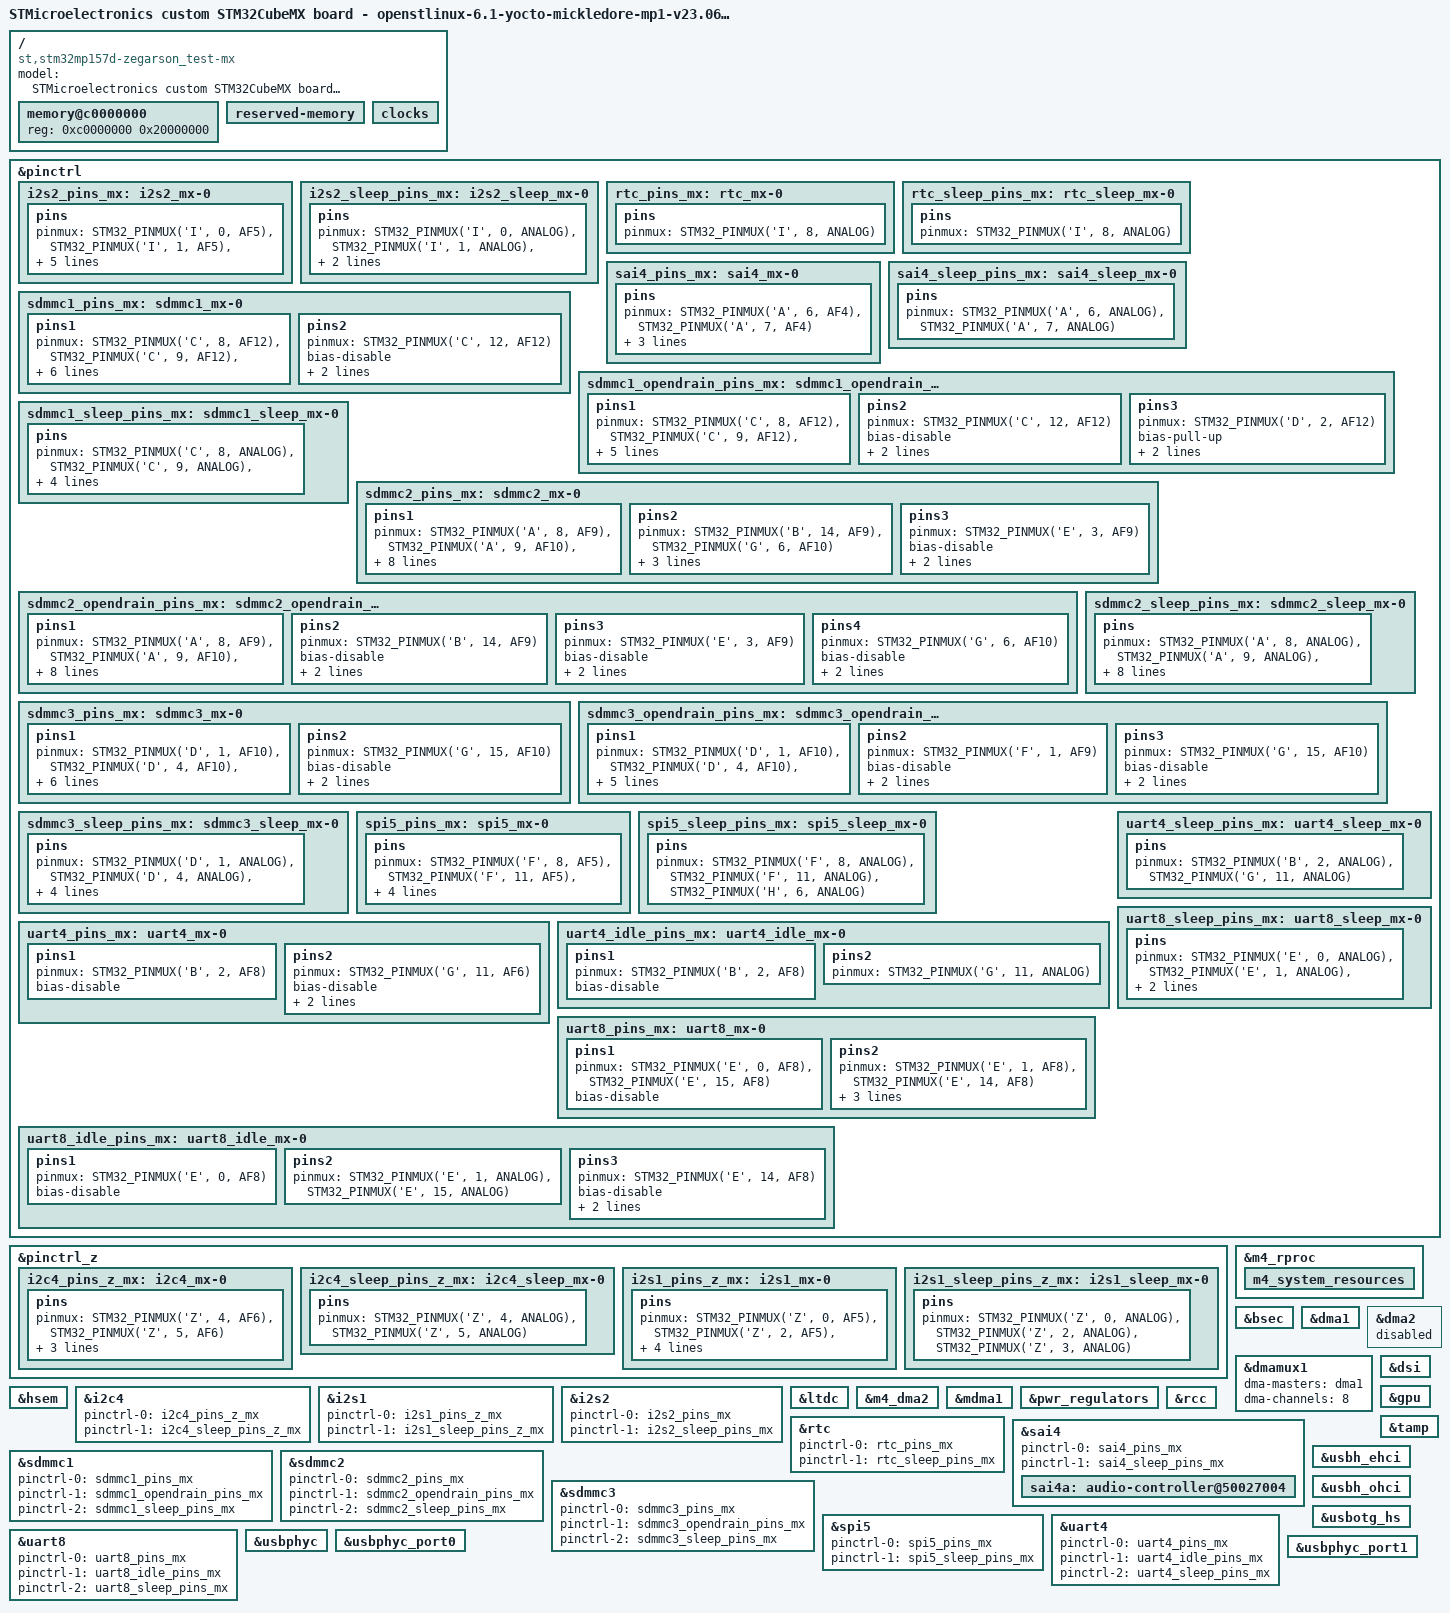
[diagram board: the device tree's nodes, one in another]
// SPDX-License-Identifier: (GPL-2.0-or-later OR BSD-3-Clause)
/*
 * Copyright (C) 2024, STMicroelectronics - All Rights Reserved
 * Author: STM32CubeMX code generation for STMicroelectronics.
 */

/* For more information on Device Tree configuration, please refer to
 * https://wiki.st.com/stm32mpu/wiki/Category:Device_tree_configuration
 */

/dts-v1/;
#include <dt-bindings/pinctrl/stm32-pinfunc.h>

#include "stm32mp157.dtsi"
#include "stm32mp15xd.dtsi"
#include "stm32mp15xxac-pinctrl.dtsi"
#include "stm32mp15-m4-srm.dtsi"

/* USER CODE BEGIN includes */
/* USER CODE END includes */

/ {
	model = "STMicroelectronics custom STM32CubeMX board - openstlinux-6.1-yocto-mickledore-mp1-v23.06.21";
	compatible = "st,stm32mp157d-zegarson_test-mx", "st,stm32mp157";

	memory@c0000000 {
		device_type = "memory";
		reg = <0xc0000000 0x20000000>;

		/* USER CODE BEGIN memory */
		/* USER CODE END memory */
	};

	reserved-memory {
		#address-cells = <1>;
		#size-cells = <1>;
		ranges;

		/* USER CODE BEGIN reserved-memory */
		/* USER CODE END reserved-memory */
	};

	/* USER CODE BEGIN root */
	/* USER CODE END root */

	clocks{

		/* USER CODE BEGIN clocks */
		/* USER CODE END clocks */
	};

}; /*root*/

&pinctrl {

	i2s2_pins_mx: i2s2_mx-0 {
		pins {
			pinmux = <STM32_PINMUX('I', 0, AF5)>, /* I2S2_WS */
					 <STM32_PINMUX('I', 1, AF5)>, /* I2S2_CK */
					 <STM32_PINMUX('I', 2, AF5)>, /* I2S2_SDI */
					 <STM32_PINMUX('I', 3, AF5)>; /* I2S2_SDO */
			bias-disable;
			drive-push-pull;
			slew-rate = <1>;
		};
	};

	i2s2_sleep_pins_mx: i2s2_sleep_mx-0 {
		pins {
			pinmux = <STM32_PINMUX('I', 0, ANALOG)>, /* I2S2_WS */
					 <STM32_PINMUX('I', 1, ANALOG)>, /* I2S2_CK */
					 <STM32_PINMUX('I', 2, ANALOG)>, /* I2S2_SDI */
					 <STM32_PINMUX('I', 3, ANALOG)>; /* I2S2_SDO */
		};
	};

	rtc_pins_mx: rtc_mx-0 {
		pins {
			pinmux = <STM32_PINMUX('I', 8, ANALOG)>; /* RTC_LSCO */
		};
	};

	rtc_sleep_pins_mx: rtc_sleep_mx-0 {
		pins {
			pinmux = <STM32_PINMUX('I', 8, ANALOG)>; /* RTC_LSCO */
		};
	};

	sai4_pins_mx: sai4_mx-0 {
		pins {
			pinmux = <STM32_PINMUX('A', 6, AF4)>, /* SAI4_CK2 */
					 <STM32_PINMUX('A', 7, AF4)>; /* SAI4_D1 */
			bias-disable;
			drive-push-pull;
			slew-rate = <0>;
		};
	};

	sai4_sleep_pins_mx: sai4_sleep_mx-0 {
		pins {
			pinmux = <STM32_PINMUX('A', 6, ANALOG)>, /* SAI4_CK2 */
					 <STM32_PINMUX('A', 7, ANALOG)>; /* SAI4_D1 */
		};
	};

	sdmmc1_pins_mx: sdmmc1_mx-0 {
		pins1 {
			pinmux = <STM32_PINMUX('C', 8, AF12)>, /* SDMMC1_D0 */
					 <STM32_PINMUX('C', 9, AF12)>, /* SDMMC1_D1 */
					 <STM32_PINMUX('C', 10, AF12)>, /* SDMMC1_D2 */
					 <STM32_PINMUX('C', 11, AF12)>, /* SDMMC1_D3 */
					 <STM32_PINMUX('D', 2, AF12)>; /* SDMMC1_CMD */
			bias-pull-up;
			drive-push-pull;
			slew-rate = <1>;
		};
		pins2 {
			pinmux = <STM32_PINMUX('C', 12, AF12)>; /* SDMMC1_CK */
			bias-disable;
			drive-push-pull;
			slew-rate = <3>;
		};
	};

	sdmmc1_opendrain_pins_mx: sdmmc1_opendrain_mx-0 {
		pins1 {
			pinmux = <STM32_PINMUX('C', 8, AF12)>, /* SDMMC1_D0 */
					 <STM32_PINMUX('C', 9, AF12)>, /* SDMMC1_D1 */
					 <STM32_PINMUX('C', 10, AF12)>, /* SDMMC1_D2 */
					 <STM32_PINMUX('C', 11, AF12)>; /* SDMMC1_D3 */
			bias-pull-up;
			drive-push-pull;
			slew-rate = <1>;
		};
		pins2 {
			pinmux = <STM32_PINMUX('C', 12, AF12)>; /* SDMMC1_CK */
			bias-disable;
			drive-push-pull;
			slew-rate = <3>;
		};
		pins3 {
			pinmux = <STM32_PINMUX('D', 2, AF12)>; /* SDMMC1_CMD */
			bias-pull-up;
			drive-open-drain;
			slew-rate = <1>;
		};
	};

	sdmmc1_sleep_pins_mx: sdmmc1_sleep_mx-0 {
		pins {
			pinmux = <STM32_PINMUX('C', 8, ANALOG)>, /* SDMMC1_D0 */
					 <STM32_PINMUX('C', 9, ANALOG)>, /* SDMMC1_D1 */
					 <STM32_PINMUX('C', 10, ANALOG)>, /* SDMMC1_D2 */
					 <STM32_PINMUX('C', 11, ANALOG)>, /* SDMMC1_D3 */
					 <STM32_PINMUX('C', 12, ANALOG)>, /* SDMMC1_CK */
					 <STM32_PINMUX('D', 2, ANALOG)>; /* SDMMC1_CMD */
		};
	};

	sdmmc2_pins_mx: sdmmc2_mx-0 {
		pins1 {
			pinmux = <STM32_PINMUX('A', 8, AF9)>, /* SDMMC2_D4 */
					 <STM32_PINMUX('A', 9, AF10)>, /* SDMMC2_D5 */
					 <STM32_PINMUX('B', 3, AF9)>, /* SDMMC2_D2 */
					 <STM32_PINMUX('B', 4, AF9)>, /* SDMMC2_D3 */
					 <STM32_PINMUX('B', 15, AF9)>, /* SDMMC2_D1 */
					 <STM32_PINMUX('C', 6, AF10)>, /* SDMMC2_D6 */
					 <STM32_PINMUX('C', 7, AF10)>; /* SDMMC2_D7 */
			bias-pull-up;
			drive-push-pull;
			slew-rate = <1>;
		};
		pins2 {
			pinmux = <STM32_PINMUX('B', 14, AF9)>, /* SDMMC2_D0 */
					 <STM32_PINMUX('G', 6, AF10)>; /* SDMMC2_CMD */
			bias-disable;
			drive-push-pull;
			slew-rate = <1>;
		};
		pins3 {
			pinmux = <STM32_PINMUX('E', 3, AF9)>; /* SDMMC2_CK */
			bias-disable;
			drive-push-pull;
			slew-rate = <3>;
		};
	};

	sdmmc2_opendrain_pins_mx: sdmmc2_opendrain_mx-0 {
		pins1 {
			pinmux = <STM32_PINMUX('A', 8, AF9)>, /* SDMMC2_D4 */
					 <STM32_PINMUX('A', 9, AF10)>, /* SDMMC2_D5 */
					 <STM32_PINMUX('B', 3, AF9)>, /* SDMMC2_D2 */
					 <STM32_PINMUX('B', 4, AF9)>, /* SDMMC2_D3 */
					 <STM32_PINMUX('B', 15, AF9)>, /* SDMMC2_D1 */
					 <STM32_PINMUX('C', 6, AF10)>, /* SDMMC2_D6 */
					 <STM32_PINMUX('C', 7, AF10)>; /* SDMMC2_D7 */
			bias-pull-up;
			drive-push-pull;
			slew-rate = <1>;
		};
		pins2 {
			pinmux = <STM32_PINMUX('B', 14, AF9)>; /* SDMMC2_D0 */
			bias-disable;
			drive-push-pull;
			slew-rate = <1>;
		};
		pins3 {
			pinmux = <STM32_PINMUX('E', 3, AF9)>; /* SDMMC2_CK */
			bias-disable;
			drive-push-pull;
			slew-rate = <3>;
		};
		pins4 {
			pinmux = <STM32_PINMUX('G', 6, AF10)>; /* SDMMC2_CMD */
			bias-disable;
			drive-open-drain;
			slew-rate = <1>;
		};
	};

	sdmmc2_sleep_pins_mx: sdmmc2_sleep_mx-0 {
		pins {
			pinmux = <STM32_PINMUX('A', 8, ANALOG)>, /* SDMMC2_D4 */
					 <STM32_PINMUX('A', 9, ANALOG)>, /* SDMMC2_D5 */
					 <STM32_PINMUX('B', 3, ANALOG)>, /* SDMMC2_D2 */
					 <STM32_PINMUX('B', 4, ANALOG)>, /* SDMMC2_D3 */
					 <STM32_PINMUX('B', 14, ANALOG)>, /* SDMMC2_D0 */
					 <STM32_PINMUX('B', 15, ANALOG)>, /* SDMMC2_D1 */
					 <STM32_PINMUX('C', 6, ANALOG)>, /* SDMMC2_D6 */
					 <STM32_PINMUX('C', 7, ANALOG)>, /* SDMMC2_D7 */
					 <STM32_PINMUX('E', 3, ANALOG)>, /* SDMMC2_CK */
					 <STM32_PINMUX('G', 6, ANALOG)>; /* SDMMC2_CMD */
		};
	};

	sdmmc3_pins_mx: sdmmc3_mx-0 {
		pins1 {
			pinmux = <STM32_PINMUX('D', 1, AF10)>, /* SDMMC3_D0 */
					 <STM32_PINMUX('D', 4, AF10)>, /* SDMMC3_D1 */
					 <STM32_PINMUX('D', 5, AF10)>, /* SDMMC3_D2 */
					 <STM32_PINMUX('D', 7, AF10)>, /* SDMMC3_D3 */
					 <STM32_PINMUX('F', 1, AF9)>; /* SDMMC3_CMD */
			bias-disable;
			drive-push-pull;
			slew-rate = <1>;
		};
		pins2 {
			pinmux = <STM32_PINMUX('G', 15, AF10)>; /* SDMMC3_CK */
			bias-disable;
			drive-push-pull;
			slew-rate = <3>;
		};
	};

	sdmmc3_opendrain_pins_mx: sdmmc3_opendrain_mx-0 {
		pins1 {
			pinmux = <STM32_PINMUX('D', 1, AF10)>, /* SDMMC3_D0 */
					 <STM32_PINMUX('D', 4, AF10)>, /* SDMMC3_D1 */
					 <STM32_PINMUX('D', 5, AF10)>, /* SDMMC3_D2 */
					 <STM32_PINMUX('D', 7, AF10)>; /* SDMMC3_D3 */
			bias-disable;
			drive-push-pull;
			slew-rate = <1>;
		};
		pins2 {
			pinmux = <STM32_PINMUX('F', 1, AF9)>; /* SDMMC3_CMD */
			bias-disable;
			drive-open-drain;
			slew-rate = <1>;
		};
		pins3 {
			pinmux = <STM32_PINMUX('G', 15, AF10)>; /* SDMMC3_CK */
			bias-disable;
			drive-push-pull;
			slew-rate = <3>;
		};
	};

	sdmmc3_sleep_pins_mx: sdmmc3_sleep_mx-0 {
		pins {
			pinmux = <STM32_PINMUX('D', 1, ANALOG)>, /* SDMMC3_D0 */
					 <STM32_PINMUX('D', 4, ANALOG)>, /* SDMMC3_D1 */
					 <STM32_PINMUX('D', 5, ANALOG)>, /* SDMMC3_D2 */
					 <STM32_PINMUX('D', 7, ANALOG)>, /* SDMMC3_D3 */
					 <STM32_PINMUX('F', 1, ANALOG)>, /* SDMMC3_CMD */
					 <STM32_PINMUX('G', 15, ANALOG)>; /* SDMMC3_CK */
		};
	};

	spi5_pins_mx: spi5_mx-0 {
		pins {
			pinmux = <STM32_PINMUX('F', 8, AF5)>, /* SPI5_MISO */
					 <STM32_PINMUX('F', 11, AF5)>, /* SPI5_MOSI */
					 <STM32_PINMUX('H', 6, AF5)>; /* SPI5_SCK */
			bias-disable;
			drive-push-pull;
			slew-rate = <1>;
		};
	};

	spi5_sleep_pins_mx: spi5_sleep_mx-0 {
		pins {
			pinmux = <STM32_PINMUX('F', 8, ANALOG)>, /* SPI5_MISO */
					 <STM32_PINMUX('F', 11, ANALOG)>, /* SPI5_MOSI */
					 <STM32_PINMUX('H', 6, ANALOG)>; /* SPI5_SCK */
		};
	};

	uart4_pins_mx: uart4_mx-0 {
		pins1 {
			pinmux = <STM32_PINMUX('B', 2, AF8)>; /* UART4_RX */
			bias-disable;
		};
		pins2 {
			pinmux = <STM32_PINMUX('G', 11, AF6)>; /* UART4_TX */
			bias-disable;
			drive-push-pull;
			slew-rate = <0>;
		};
	};

	uart4_idle_pins_mx: uart4_idle_mx-0 {
		pins1 {
			pinmux = <STM32_PINMUX('B', 2, AF8)>; /* UART4_RX */
			bias-disable;
		};
		pins2 {
			pinmux = <STM32_PINMUX('G', 11, ANALOG)>; /* UART4_TX */
		};
	};

	uart4_sleep_pins_mx: uart4_sleep_mx-0 {
		pins {
			pinmux = <STM32_PINMUX('B', 2, ANALOG)>, /* UART4_RX */
					 <STM32_PINMUX('G', 11, ANALOG)>; /* UART4_TX */
		};
	};

	uart8_pins_mx: uart8_mx-0 {
		pins1 {
			pinmux = <STM32_PINMUX('E', 0, AF8)>, /* UART8_RX */
					 <STM32_PINMUX('E', 15, AF8)>; /* UART8_CTS */
			bias-disable;
		};
		pins2 {
			pinmux = <STM32_PINMUX('E', 1, AF8)>, /* UART8_TX */
					 <STM32_PINMUX('E', 14, AF8)>; /* UART8_RTS */
			bias-disable;
			drive-push-pull;
			slew-rate = <0>;
		};
	};

	uart8_idle_pins_mx: uart8_idle_mx-0 {
		pins1 {
			pinmux = <STM32_PINMUX('E', 0, AF8)>; /* UART8_RX */
			bias-disable;
		};
		pins2 {
			pinmux = <STM32_PINMUX('E', 1, ANALOG)>, /* UART8_TX */
					 <STM32_PINMUX('E', 15, ANALOG)>; /* UART8_CTS */
		};
		pins3 {
			pinmux = <STM32_PINMUX('E', 14, AF8)>; /* UART8_RTS */
			bias-disable;
			drive-push-pull;
			slew-rate = <0>;
		};
	};

	uart8_sleep_pins_mx: uart8_sleep_mx-0 {
		pins {
			pinmux = <STM32_PINMUX('E', 0, ANALOG)>, /* UART8_RX */
					 <STM32_PINMUX('E', 1, ANALOG)>, /* UART8_TX */
					 <STM32_PINMUX('E', 14, ANALOG)>, /* UART8_RTS */
					 <STM32_PINMUX('E', 15, ANALOG)>; /* UART8_CTS */
		};
	};

	/* USER CODE BEGIN pinctrl */
	/* USER CODE END pinctrl */
};

&pinctrl_z {

	i2c4_pins_z_mx: i2c4_mx-0 {
		pins {
			pinmux = <STM32_PINMUX('Z', 4, AF6)>, /* I2C4_SCL */
					 <STM32_PINMUX('Z', 5, AF6)>; /* I2C4_SDA */
			bias-disable;
			drive-open-drain;
			slew-rate = <0>;
		};
	};

	i2c4_sleep_pins_z_mx: i2c4_sleep_mx-0 {
		pins {
			pinmux = <STM32_PINMUX('Z', 4, ANALOG)>, /* I2C4_SCL */
					 <STM32_PINMUX('Z', 5, ANALOG)>; /* I2C4_SDA */
		};
	};

	i2s1_pins_z_mx: i2s1_mx-0 {
		pins {
			pinmux = <STM32_PINMUX('Z', 0, AF5)>, /* I2S1_CK */
					 <STM32_PINMUX('Z', 2, AF5)>, /* I2S1_SDO */
					 <STM32_PINMUX('Z', 3, AF5)>; /* I2S1_WS */
			bias-disable;
			drive-push-pull;
			slew-rate = <1>;
		};
	};

	i2s1_sleep_pins_z_mx: i2s1_sleep_mx-0 {
		pins {
			pinmux = <STM32_PINMUX('Z', 0, ANALOG)>, /* I2S1_CK */
					 <STM32_PINMUX('Z', 2, ANALOG)>, /* I2S1_SDO */
					 <STM32_PINMUX('Z', 3, ANALOG)>; /* I2S1_WS */
		};
	};

	/* USER CODE BEGIN pinctrl_z */
	/* USER CODE END pinctrl_z */
};

&m4_rproc{
	status = "okay";

	/* USER CODE BEGIN m4_rproc */
	/* USER CODE END m4_rproc */

	m4_system_resources{
		status = "okay";

		/* USER CODE BEGIN m4_system_resources */
		/* USER CODE END m4_system_resources */
	};
};

&bsec{
	status = "okay";

	/* USER CODE BEGIN bsec */
	/* USER CODE END bsec */
};

&dma1{
	status = "okay";

	/* USER CODE BEGIN dma1 */
	/* USER CODE END dma1 */
};

&dma2{
	status = "disabled";

	/* USER CODE BEGIN dma2 */
	/* USER CODE END dma2 */
};

&dmamux1{
	status = "okay";

	dma-masters = <&dma1>;
	dma-channels = <8>;

	/* USER CODE BEGIN dmamux1 */
	/* USER CODE END dmamux1 */
};

&dsi{
	status = "okay";

	/* USER CODE BEGIN dsi */
	/* USER CODE END dsi */
};

&gpu{
	status = "okay";

	/* USER CODE BEGIN gpu */
	/* USER CODE END gpu */
};

&hsem{
	status = "okay";

	/* USER CODE BEGIN hsem */
	/* USER CODE END hsem */
};

&i2c4{
	pinctrl-names = "default", "sleep";
	pinctrl-0 = <&i2c4_pins_z_mx>;
	pinctrl-1 = <&i2c4_sleep_pins_z_mx>;
	status = "okay";

	/* USER CODE BEGIN i2c4 */
	/* USER CODE END i2c4 */
};

&i2s1{
	pinctrl-names = "default", "sleep";
	pinctrl-0 = <&i2s1_pins_z_mx>;
	pinctrl-1 = <&i2s1_sleep_pins_z_mx>;
	status = "okay";

	/* USER CODE BEGIN i2s1 */
	/* USER CODE END i2s1 */
};

&i2s2{
	pinctrl-names = "default", "sleep";
	pinctrl-0 = <&i2s2_pins_mx>;
	pinctrl-1 = <&i2s2_sleep_pins_mx>;
	status = "okay";

	/* USER CODE BEGIN i2s2 */
	/* USER CODE END i2s2 */
};

&ltdc{
	status = "okay";

	/* USER CODE BEGIN ltdc */
	/* USER CODE END ltdc */
};

&m4_dma2{
	status = "okay";

	/* USER CODE BEGIN m4_dma2 */
	/* USER CODE END m4_dma2 */
};

&mdma1{
	status = "okay";

	/* USER CODE BEGIN mdma1 */
	/* USER CODE END mdma1 */
};

&pwr_regulators{
	status = "okay";

	/* USER CODE BEGIN pwr_regulators */
	/* USER CODE END pwr_regulators */
};

&rcc{
	status = "okay";

	/* USER CODE BEGIN rcc */
	/* USER CODE END rcc */
};

&rtc{
	pinctrl-names = "default", "sleep";
	pinctrl-0 = <&rtc_pins_mx>;
	pinctrl-1 = <&rtc_sleep_pins_mx>;
	status = "okay";

	/* USER CODE BEGIN rtc */
	/* USER CODE END rtc */
};

&sai4{
	pinctrl-names = "default", "sleep";
	pinctrl-0 = <&sai4_pins_mx>;
	pinctrl-1 = <&sai4_sleep_pins_mx>;
	status = "okay";

	/* USER CODE BEGIN sai4 */
	/* USER CODE END sai4 */

	sai4a:audio-controller@50027004{
		status = "okay";

		/* USER CODE BEGIN sai4a */
		/* USER CODE END sai4a */
	};
};

&sdmmc1{
	pinctrl-names = "default", "opendrain", "sleep";
	pinctrl-0 = <&sdmmc1_pins_mx>;
	pinctrl-1 = <&sdmmc1_opendrain_pins_mx>;
	pinctrl-2 = <&sdmmc1_sleep_pins_mx>;
	status = "okay";

	/* USER CODE BEGIN sdmmc1 */
	/* USER CODE END sdmmc1 */
};

&sdmmc2{
	pinctrl-names = "default", "opendrain", "sleep";
	pinctrl-0 = <&sdmmc2_pins_mx>;
	pinctrl-1 = <&sdmmc2_opendrain_pins_mx>;
	pinctrl-2 = <&sdmmc2_sleep_pins_mx>;
	status = "okay";

	/* USER CODE BEGIN sdmmc2 */
	/* USER CODE END sdmmc2 */
};

&sdmmc3{
	pinctrl-names = "default", "opendrain", "sleep";
	pinctrl-0 = <&sdmmc3_pins_mx>;
	pinctrl-1 = <&sdmmc3_opendrain_pins_mx>;
	pinctrl-2 = <&sdmmc3_sleep_pins_mx>;
	status = "okay";

	/* USER CODE BEGIN sdmmc3 */
	/* USER CODE END sdmmc3 */
};

&spi5{
	pinctrl-names = "default", "sleep";
	pinctrl-0 = <&spi5_pins_mx>;
	pinctrl-1 = <&spi5_sleep_pins_mx>;
	status = "okay";

	/* USER CODE BEGIN spi5 */
	/* USER CODE END spi5 */
};

&tamp{
	status = "okay";

	/* USER CODE BEGIN tamp */
	/* USER CODE END tamp */
};

&uart4{
	pinctrl-names = "default", "idle", "sleep";
	pinctrl-0 = <&uart4_pins_mx>;
	pinctrl-1 = <&uart4_idle_pins_mx>;
	pinctrl-2 = <&uart4_sleep_pins_mx>;
	status = "okay";

	/* USER CODE BEGIN uart4 */
	/* USER CODE END uart4 */
};

&uart8{
	pinctrl-names = "default", "idle", "sleep";
	pinctrl-0 = <&uart8_pins_mx>;
	pinctrl-1 = <&uart8_idle_pins_mx>;
	pinctrl-2 = <&uart8_sleep_pins_mx>;
	status = "okay";

	/* USER CODE BEGIN uart8 */
	/* USER CODE END uart8 */
};

&usbh_ehci{
	status = "okay";

	/* USER CODE BEGIN usbh_ehci */
	/* USER CODE END usbh_ehci */
};

&usbh_ohci{
	status = "okay";

	/* USER CODE BEGIN usbh_ohci */
	/* USER CODE END usbh_ohci */
};

&usbotg_hs{
	status = "okay";

	/* USER CODE BEGIN usbotg_hs */
	/* USER CODE END usbotg_hs */
};

&usbphyc{
	status = "okay";

	/* USER CODE BEGIN usbphyc */
	/* USER CODE END usbphyc */
};

&usbphyc_port0{
	status = "okay";

	/* USER CODE BEGIN usbphyc_port0 */
	/* USER CODE END usbphyc_port0 */
};

&usbphyc_port1{
	status = "okay";

	/* USER CODE BEGIN usbphyc_port1 */
	/* USER CODE END usbphyc_port1 */
};

/* USER CODE BEGIN addons */
/* USER CODE END addons */

